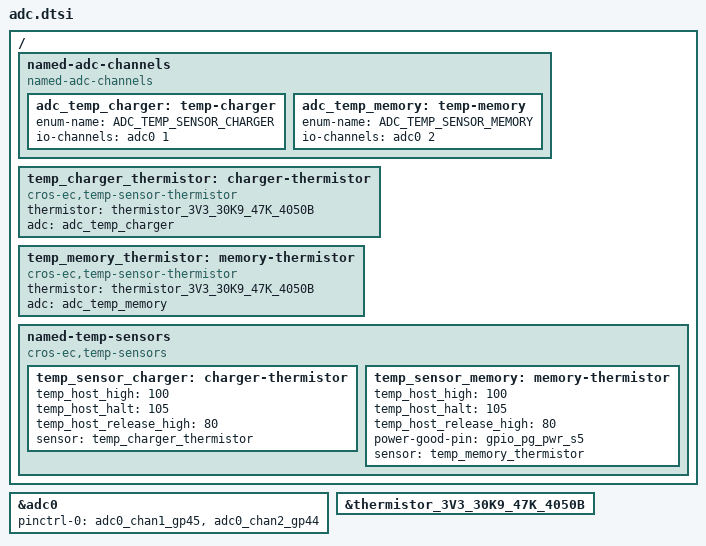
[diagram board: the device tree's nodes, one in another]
/* Copyright 2023 The ChromiumOS Authors
 * Use of this source code is governed by a BSD-style license that can be
 * found in the LICENSE file.
 */

#include <cros/thermistor/thermistor.dtsi>

/ {
	named-adc-channels {
		compatible = "named-adc-channels";

		adc_temp_charger: temp-charger {
			enum-name = "ADC_TEMP_SENSOR_CHARGER";
			io-channels = <&adc0 1>;
		};
		adc_temp_memory: temp-memory {
			enum-name = "ADC_TEMP_SENSOR_MEMORY";
			io-channels = <&adc0 2>;
		};
	};

	temp_charger_thermistor: charger-thermistor {
		compatible = "cros-ec,temp-sensor-thermistor";
		thermistor = <&thermistor_3V3_30K9_47K_4050B>;
		adc = <&adc_temp_charger>;
	};

	temp_memory_thermistor: memory-thermistor {
		compatible = "cros-ec,temp-sensor-thermistor";
		thermistor = <&thermistor_3V3_30K9_47K_4050B>;
		adc = <&adc_temp_memory>;
	};

	named-temp-sensors {
		compatible = "cros-ec,temp-sensors";
		temp_sensor_charger: charger-thermistor {
			temp_host_high = <100>;
			temp_host_halt = <105>;
			temp_host_release_high = <80>;
			sensor = <&temp_charger_thermistor>;
		};

		temp_sensor_memory: memory-thermistor {
			temp_host_high = <100>;
			temp_host_halt = <105>;
			temp_host_release_high = <80>;
			power-good-pin = <&gpio_pg_pwr_s5>;
			sensor = <&temp_memory_thermistor>;
		};
	};
};

&adc0 {
	status = "okay";
	pinctrl-0 = <&adc0_chan1_gp45
		     &adc0_chan2_gp44>;
	pinctrl-names = "default";
};

&thermistor_3V3_30K9_47K_4050B {
	status = "okay";
};
